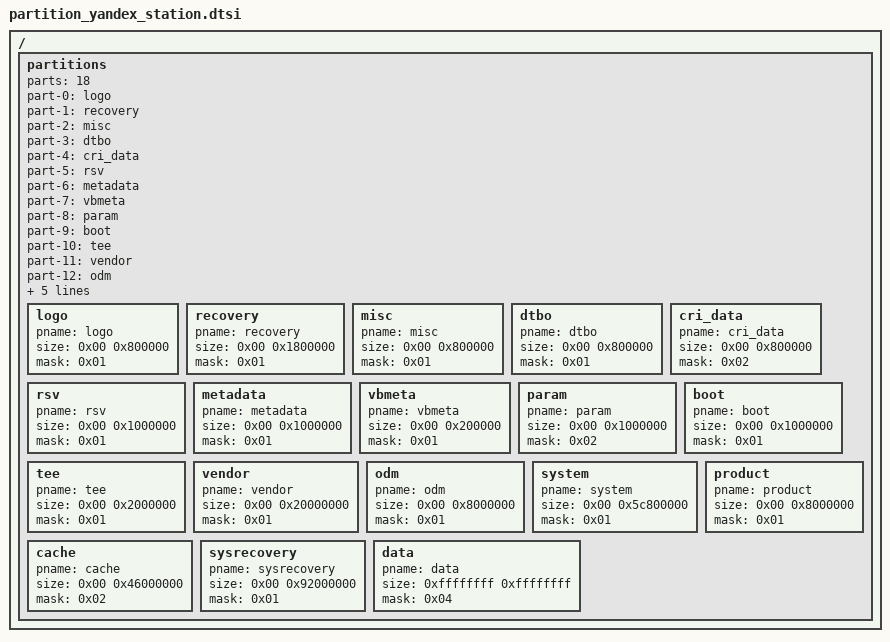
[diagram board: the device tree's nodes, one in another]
/*
 * Yandex Station Max partition table for Amlogic SM1 / S905X3
 */

/ {
	partitions: partitions {
		parts = < 18 >;
		part-0 = < &logo >;
		part-1 = < &recovery >;
		part-2 = < &misc >;
		part-3 = < &dtbo >;
		part-4 = < &cri_data >;
		part-5 = < &rsv >;
		part-6 = < &metadata >;
		part-7 = < &vbmeta >;
		part-8 = < &param >;
		part-9 = < &boot >;
		part-10 = < &tee >;
		part-11 = < &vendor >;
		part-12 = < &odm >;
		part-13 = < &system >;
		part-14 = < &product >;
		part-15 = < &cache >;
		part-16 = < &sysrecovery >;
		part-17 = < &data >;

		logo: logo {
			pname = "logo";
			size = < 0x00 0x800000 >;
			mask = < 0x01 >;
		};

		recovery: recovery {
			pname = "recovery";
			size = < 0x00 0x1800000 >;
			mask = < 0x01 >;
		};

		misc: misc {
			pname = "misc";
			size = < 0x00 0x800000 >;
			mask = < 0x01 >;
		};

		dtbo: dtbo {
			pname = "dtbo";
			size = < 0x00 0x800000 >;
			mask = < 0x01 >;
		};

		cri_data: cri_data {
			pname = "cri_data";
			size = < 0x00 0x800000 >;
			mask = < 0x02 >;
		};

		rsv: rsv {
			pname = "rsv";
			size = < 0x00 0x1000000 >;
			mask = < 0x01 >;
		};

		metadata: metadata {
			pname = "metadata";
			size = < 0x00 0x1000000 >;
			mask = < 0x01 >;
		};

		vbmeta: vbmeta {
			pname = "vbmeta";
			size = < 0x00 0x200000 >;
			mask = < 0x01 >;
		};

		param: param {
			pname = "param";
			size = < 0x00 0x1000000 >;
			mask = < 0x02 >;
		};

		boot: boot {
			pname = "boot";
			size = < 0x00 0x1000000 >;
			mask = < 0x01 >;
		};

		tee: tee {
			pname = "tee";
			size = < 0x00 0x2000000 >;
			mask = < 0x01 >;
		};

		vendor: vendor {
			pname = "vendor";
			size = < 0x00 0x20000000 >;
			mask = < 0x01 >;
		};

		odm: odm {
			pname = "odm";
			size = < 0x00 0x8000000 >;
			mask = < 0x01 >;
		};

	system: system {
			pname = "system";
			size = < 0x00 0x5c800000 >;
			mask = < 0x01 >;
		};

		product: product {
			pname = "product";
			size = < 0x00 0x8000000 >;
			mask = < 0x01 >;
		};

		cache: cache {
			pname = "cache";
			size = < 0x00 0x46000000 >;
			mask = < 0x02 >;
		};

		sysrecovery: sysrecovery {
			pname = "sysrecovery";
			size = < 0x00 0x92000000 >;
			mask = < 0x01 >;
		};

		data: data {
			pname = "data";
			size = < 0xffffffff 0xffffffff >;
			mask = < 0x04 >;
		};
	};
};
